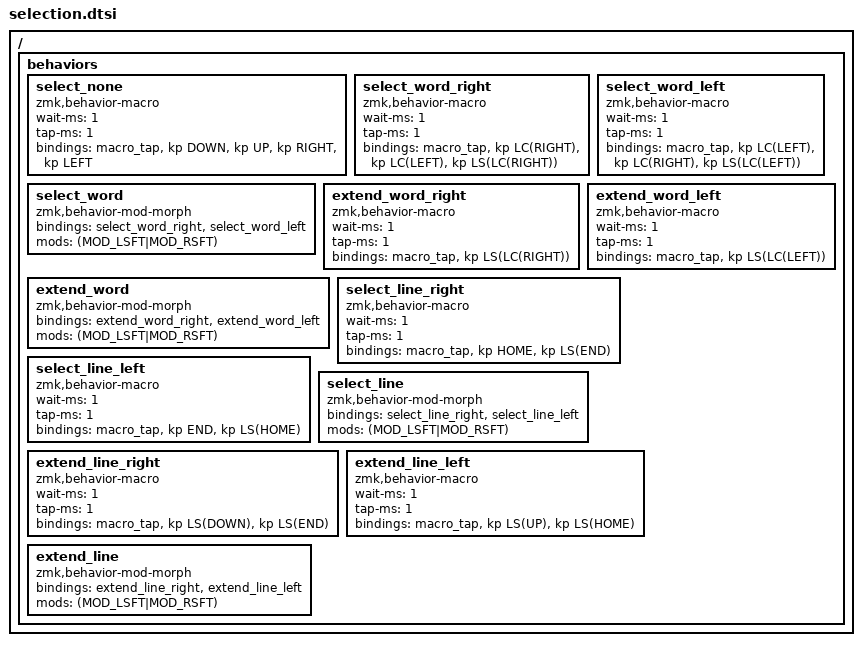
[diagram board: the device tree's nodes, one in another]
/ {
	behaviors {

		select_none: select_none {
			compatible = "zmk,behavior-macro";
			#binding-cells = <0>;
			wait-ms = <1>;
			tap-ms = <1>;
			bindings = <&macro_tap &kp DOWN &kp UP &kp RIGHT &kp LEFT>;
		};
		
		#define select_all kp LC(A)
		
		select_word_right: select_word_right {
			compatible = "zmk,behavior-macro";
			#binding-cells = <0>;
			wait-ms = <1>;
			tap-ms = <1>;
			bindings = <&macro_tap &kp LC(RIGHT) &kp LC(LEFT) &kp LS(LC(RIGHT))>;
		};
		select_word_left: select_word_left {
			compatible = "zmk,behavior-macro";
			#binding-cells = <0>;
			wait-ms = <1>;
			tap-ms = <1>;
			bindings = <&macro_tap &kp LC(LEFT) &kp LC(RIGHT) &kp LS(LC(LEFT))>;
		};
		select_word: select_word {
			compatible = "zmk,behavior-mod-morph";
			#binding-cells = <0>;
			bindings = <&select_word_right>, <&select_word_left>;
			mods = <(MOD_LSFT|MOD_RSFT)>;
		};
		
		extend_word_right: extend_word_right {
			compatible = "zmk,behavior-macro";
			#binding-cells = <0>;
			wait-ms = <1>;
			tap-ms = <1>;
			bindings = <&macro_tap &kp LS(LC(RIGHT))>;
		};
		extend_word_left: extend_word_left {
			compatible = "zmk,behavior-macro";
			#binding-cells = <0>;
			wait-ms = <1>;
			tap-ms = <1>;
			bindings = <&macro_tap &kp LS(LC(LEFT))>;
		};
		
		extend_word: extend_word {
			compatible = "zmk,behavior-mod-morph";
			#binding-cells = <0>;
			bindings = <&extend_word_right>, <&extend_word_left>;
			mods = <(MOD_LSFT|MOD_RSFT)>;
		};
		
		select_line_right: select_line_right {
			compatible = "zmk,behavior-macro";
			#binding-cells = <0>;
			wait-ms = <1>;
			tap-ms = <1>;
			bindings = <&macro_tap &kp HOME &kp LS(END)>;
		};
		select_line_left: select_line_left {
			compatible = "zmk,behavior-macro";
			#binding-cells = <0>;
			wait-ms = <1>;
			tap-ms = <1>;
			bindings = <&macro_tap &kp END &kp LS(HOME)>;
		};
		
		select_line: select_line {
			compatible = "zmk,behavior-mod-morph";
			#binding-cells = <0>;
			bindings = <&select_line_right>, <&select_line_left>;
			mods = <(MOD_LSFT|MOD_RSFT)>;
		};
		
		extend_line_right: extend_line_right {
			compatible = "zmk,behavior-macro";
			#binding-cells = <0>;
			wait-ms = <1>;
			tap-ms = <1>;
			bindings = <&macro_tap &kp LS(DOWN) &kp LS(END)>;
		};
		extend_line_left: extend_line_left {
			compatible = "zmk,behavior-macro";
			#binding-cells = <0>;
			wait-ms = <1>;
			tap-ms = <1>;
			bindings = <&macro_tap &kp LS(UP) &kp LS(HOME)>;
		};
		
		extend_line: extend_line {
			compatible = "zmk,behavior-mod-morph";
			#binding-cells = <0>;
			bindings = <&extend_line_right>, <&extend_line_left>;
			mods = <(MOD_LSFT|MOD_RSFT)>;
		};
		
	};
};
